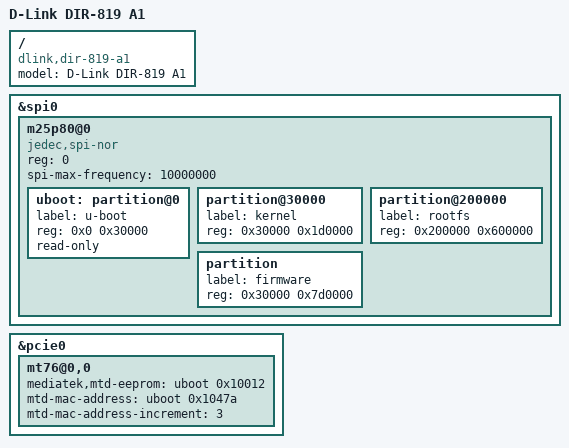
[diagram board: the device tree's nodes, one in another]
/dts-v1/;

#include "tbs.dtsi"

/ {
	compatible = "dlink,dir-819-a1", "ralink,mt7620a-soc";
	model = "D-Link DIR-819 A1";
};

&spi0 {
	status = "okay";

	m25p80@0 {
		#address-cells = <1>;
		#size-cells = <1>;
		compatible = "jedec,spi-nor";
		reg = <0>;
		spi-max-frequency = <10000000>;

		uboot: partition@0 {
			label = "u-boot";
			reg = <0x0 0x30000>;
			read-only;
		};

		partition@30000 {
			label = "kernel";
			reg = <0x30000 0x1d0000>;
		};

		partition@200000 {
			label = "rootfs";
			reg = <0x200000 0x600000>;
		};

		partition {
			label = "firmware";
			reg = <0x30000 0x7d0000>;
		};
	};
};

&pcie0 {
	mt76@0,0 {
		mediatek,mtd-eeprom = <&uboot 0x10012>;
		mtd-mac-address = <&uboot 0x1047a>;
		mtd-mac-address-increment = <3>;
	};
};
